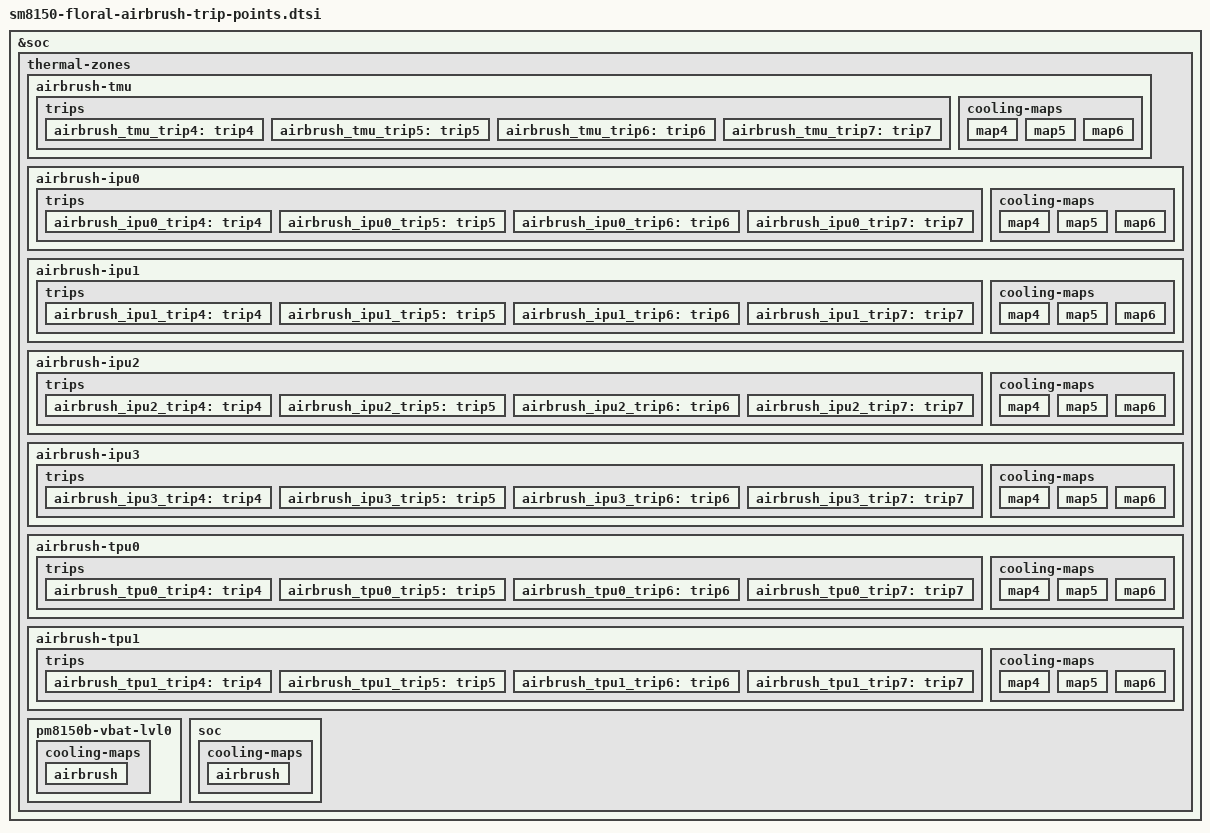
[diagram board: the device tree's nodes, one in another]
/*
 * Copyright (c) 2016 Samsung Electronics Co., Ltd.
 *		http://www.samsung.com
 *
 * This program is free software; you can redistribute it and/or modify
 * it under the terms of the GNU General Public License version 2 as
 * published by the Free Software Foundation.
 *
 */
 #include <dt-bindings/thermal/thermal.h>

&soc {
	thermal-zones {
		airbrush-tmu {
			/*
			 * TMU is able to emit interrupt to update the thermal
			 * zone while temperature going across the trip points.
			 * Also, each write to emul_temp will always update the
			 * thermal zone. So we set the polling-delay-* to 0.
			 */
			polling-delay-passive = <0>;
			polling-delay = <0>;
			thermal-sensors = <&airbrush_tmu 0>;

			trips {
			/include/ "sm8150-floral-airbrush-dummy-trips.dtsi"
				airbrush_tmu_trip4: trip4 {
					temperature = <65000>;
					hysteresis = <1000>;
					type = "passive";
				};
				airbrush_tmu_trip5: trip5 {
					temperature = <75000>;
					hysteresis = <1000>;
					type = "passive";
				};
				airbrush_tmu_trip6: trip6 {
					temperature = <85000>;
					hysteresis = <1000>;
					type = "passive";
				};
				airbrush_tmu_trip7: trip7 {
					temperature = <90000>;
					hysteresis = <1000>;
					type = "hot";
				};
			};
			cooling-maps {
				map4 {
					trip = <&airbrush_tmu_trip4>;
					cooling-device =
						<&abc_cooling_internal 1 1>;
				};
				map5 {
					trip = <&airbrush_tmu_trip5>;
					cooling-device =
						<&abc_cooling_internal 2 2>;
				};
				map6 {
					trip = <&airbrush_tmu_trip6>;
					cooling-device =
						<&abc_cooling_internal 3 3>;
				};
			};
		};

		airbrush-ipu0 {
			polling-delay-passive = <0>;
			polling-delay = <0>;
			thermal-sensors = <&airbrush_tmu 1>;
			trips {
			/include/ "sm8150-floral-airbrush-dummy-trips.dtsi"
				airbrush_ipu0_trip4: trip4 {
					temperature = <65000>;
					hysteresis = <1000>;
					type = "passive";
				};
				airbrush_ipu0_trip5: trip5 {
					temperature = <75000>;
					hysteresis = <1000>;
					type = "passive";
				};
				airbrush_ipu0_trip6: trip6 {
					temperature = <85000>;
					hysteresis = <1000>;
					type = "passive";
				};
				airbrush_ipu0_trip7: trip7 {
					temperature = <90000>;
					hysteresis = <1000>;
					type = "hot";
				};
			};
			cooling-maps {
				map4 {
					trip = <&airbrush_ipu0_trip4>;
					cooling-device =
						<&abc_cooling_internal 1 1>;
				};
				map5 {
					trip = <&airbrush_ipu0_trip5>;
					cooling-device =
						<&abc_cooling_internal 2 2>;
				};
				map6 {
					trip = <&airbrush_ipu0_trip6>;
					cooling-device =
						<&abc_cooling_internal 3 3>;
				};
			};
		};

		airbrush-ipu1 {
			polling-delay-passive = <0>;
			polling-delay = <0>;
			thermal-sensors = <&airbrush_tmu 2>;
			trips {
			/include/ "sm8150-floral-airbrush-dummy-trips.dtsi"
				airbrush_ipu1_trip4: trip4 {
					temperature = <65000>;
					hysteresis = <1000>;
					type = "passive";
				};
				airbrush_ipu1_trip5: trip5 {
					temperature = <75000>;
					hysteresis = <1000>;
					type = "passive";
				};
				airbrush_ipu1_trip6: trip6 {
					temperature = <85000>;
					hysteresis = <1000>;
					type = "passive";
				};
				airbrush_ipu1_trip7: trip7 {
					temperature = <90000>;
					hysteresis = <1000>;
					type = "hot";
				};
			};
			cooling-maps {
				map4 {
					trip = <&airbrush_ipu1_trip4>;
					cooling-device =
						<&abc_cooling_internal 1 1>;
				};
				map5 {
					trip = <&airbrush_ipu1_trip5>;
					cooling-device =
						<&abc_cooling_internal 2 2>;
				};
				map6 {
					trip = <&airbrush_ipu1_trip6>;
					cooling-device =
						<&abc_cooling_internal 3 3>;
				};
			};
		};

		airbrush-ipu2 {
			polling-delay-passive = <0>;
			polling-delay = <0>;
			thermal-sensors = <&airbrush_tmu 3>;
			trips {
			/include/ "sm8150-floral-airbrush-dummy-trips.dtsi"
				airbrush_ipu2_trip4: trip4 {
					temperature = <65000>;
					hysteresis = <1000>;
					type = "passive";
				};
				airbrush_ipu2_trip5: trip5 {
					temperature = <75000>;
					hysteresis = <1000>;
					type = "passive";
				};
				airbrush_ipu2_trip6: trip6 {
					temperature = <85000>;
					hysteresis = <1000>;
					type = "passive";
				};
				airbrush_ipu2_trip7: trip7 {
					temperature = <90000>;
					hysteresis = <1000>;
					type = "hot";
				};
			};
			cooling-maps {
				map4 {
					trip = <&airbrush_ipu2_trip4>;
					cooling-device =
						<&abc_cooling_internal 1 1>;
				};
				map5 {
					trip = <&airbrush_ipu2_trip5>;
					cooling-device =
						<&abc_cooling_internal 2 2>;
				};
				map6 {
					trip = <&airbrush_ipu2_trip6>;
					cooling-device =
						<&abc_cooling_internal 3 3>;
				};
			};
		};

		airbrush-ipu3 {
			polling-delay-passive = <0>;
			polling-delay = <0>;
			thermal-sensors = <&airbrush_tmu 4>;
			trips {
			/include/ "sm8150-floral-airbrush-dummy-trips.dtsi"
				airbrush_ipu3_trip4: trip4 {
					temperature = <65000>;
					hysteresis = <1000>;
					type = "passive";
				};
				airbrush_ipu3_trip5: trip5 {
					temperature = <75000>;
					hysteresis = <1000>;
					type = "passive";
				};
				airbrush_ipu3_trip6: trip6 {
					temperature = <85000>;
					hysteresis = <1000>;
					type = "passive";
				};
				airbrush_ipu3_trip7: trip7 {
					temperature = <90000>;
					hysteresis = <1000>;
					type = "hot";
				};
			};
			cooling-maps {
				map4 {
					trip = <&airbrush_ipu3_trip4>;
					cooling-device =
						<&abc_cooling_internal 1 1>;
				};
				map5 {
					trip = <&airbrush_ipu3_trip5>;
					cooling-device =
						<&abc_cooling_internal 2 2>;
				};
				map6 {
					trip = <&airbrush_ipu3_trip6>;
					cooling-device =
						<&abc_cooling_internal 3 3>;
				};
			};
		};

		airbrush-tpu0 {
			polling-delay-passive = <0>;
			polling-delay = <0>;
			thermal-sensors = <&airbrush_tmu 5>;
			trips {
			/include/ "sm8150-floral-airbrush-dummy-trips.dtsi"
				airbrush_tpu0_trip4: trip4 {
					temperature = <65000>;
					hysteresis = <1000>;
					type = "passive";
				};
				airbrush_tpu0_trip5: trip5 {
					temperature = <75000>;
					hysteresis = <1000>;
					type = "passive";
				};
				airbrush_tpu0_trip6: trip6 {
					temperature = <85000>;
					hysteresis = <1000>;
					type = "passive";
				};
				airbrush_tpu0_trip7: trip7 {
					temperature = <90000>;
					hysteresis = <1000>;
					type = "hot";
				};
			};
			cooling-maps {
				map4 {
					trip = <&airbrush_tpu0_trip4>;
					cooling-device =
						<&abc_cooling_internal 1 1>;
				};
				map5 {
					trip = <&airbrush_tpu0_trip5>;
					cooling-device =
						<&abc_cooling_internal 2 2>;
				};
				map6 {
					trip = <&airbrush_tpu0_trip6>;
					cooling-device =
						<&abc_cooling_internal 3 3>;
				};
			};
		};

		airbrush-tpu1 {
			polling-delay-passive = <0>;
			polling-delay = <0>;
			thermal-sensors = <&airbrush_tmu 6>;
			trips {
			/include/ "sm8150-floral-airbrush-dummy-trips.dtsi"
				airbrush_tpu1_trip4: trip4 {
					temperature = <65000>;
					hysteresis = <1000>;
					type = "passive";
				};
				airbrush_tpu1_trip5: trip5 {
					temperature = <75000>;
					hysteresis = <1000>;
					type = "passive";
				};
				airbrush_tpu1_trip6: trip6 {
					temperature = <85000>;
					hysteresis = <1000>;
					type = "passive";
				};
				airbrush_tpu1_trip7: trip7 {
					temperature = <90000>;
					hysteresis = <1000>;
					type = "hot";
				};
			};
			cooling-maps {
				map4 {
					trip = <&airbrush_tpu1_trip4>;
					cooling-device =
						<&abc_cooling_internal 1 1>;
				};
				map5 {
					trip = <&airbrush_tpu1_trip5>;
					cooling-device =
						<&abc_cooling_internal 2 2>;
				};
				map6 {
					trip = <&airbrush_tpu1_trip6>;
					cooling-device =
						<&abc_cooling_internal 3 3>;
				};
			};
		};

		pm8150b-vbat-lvl0 {
			cooling-maps {
				airbrush {
					trip = <&vbat_lvl0>;
					cooling-device = <&abc_cooling
						THERMAL_NO_LIMIT
						THERMAL_NO_LIMIT>;
				};
			};
		};

		soc {
			cooling-maps {
				airbrush {
					trip = <&soc_trip>;
					cooling-device = <&abc_cooling
						THERMAL_NO_LIMIT
						THERMAL_NO_LIMIT>;
				};
			};
		};
	};
};

